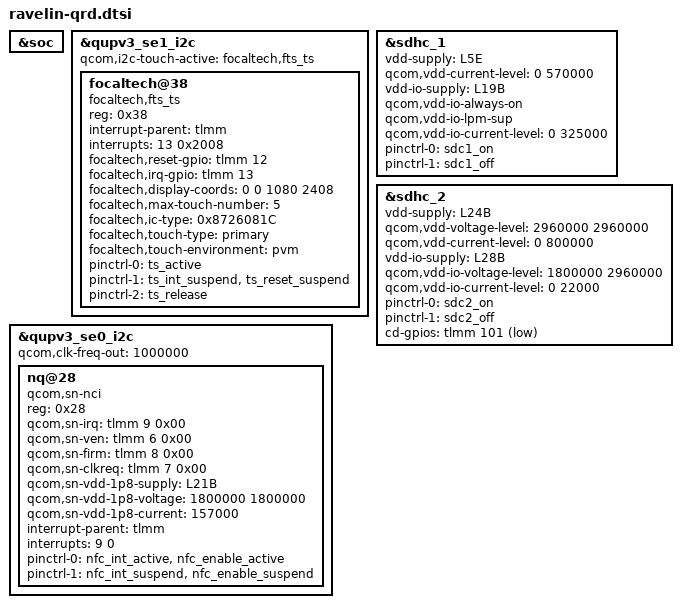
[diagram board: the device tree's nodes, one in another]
#include "ravelin-pmic-overlay.dtsi"
#include "ravelin-pmi632.dtsi"

&soc {
};

&qupv3_se1_i2c {
	#address-cells = <1>;
	#size-cells = <0>;

	status = "ok";
	qcom,i2c-touch-active = "focaltech,fts_ts";

	focaltech@38 {
		compatible = "focaltech,fts_ts";
		status = "ok";
		reg = <0x38>;

		interrupt-parent = <&tlmm>;
		interrupts = <13 0x2008>;
		focaltech,reset-gpio = <&tlmm 12 0x00>;
		focaltech,irq-gpio = <&tlmm 13 0x2008>;
		focaltech,display-coords = <0 0 1080 2408>;
		focaltech,max-touch-number = <5>;
		focaltech,ic-type = <0x8726081C>;
		focaltech,touch-type = "primary";
		focaltech,touch-environment = "pvm";

		pinctrl-names = "pmx_ts_active","pmx_ts_suspend","pmx_ts_release";
		pinctrl-0 = <&ts_active>;
		pinctrl-1 = <&ts_int_suspend &ts_reset_suspend>;
		pinctrl-2 = <&ts_release>;
	};
};

&sdhc_1 {
	status = "ok";
	vdd-supply = <&L5E>;
	qcom,vdd-current-level = <0 570000>;

	vdd-io-supply = <&L19B>;
	qcom,vdd-io-always-on;
	qcom,vdd-io-lpm-sup;
	qcom,vdd-io-current-level = <0 325000>;

	pinctrl-names = "default", "sleep";
	pinctrl-0 = <&sdc1_on>;
	pinctrl-1 = <&sdc1_off>;
};

&sdhc_2 {
	status = "ok";
	vdd-supply = <&L24B>;
	qcom,vdd-voltage-level = <2960000 2960000>;
	qcom,vdd-current-level = <0 800000>;

	vdd-io-supply = <&L28B>;
	qcom,vdd-io-voltage-level = <1800000 2960000>;
	qcom,vdd-io-current-level = <0 22000>;

	pinctrl-names = "default", "sleep";
	pinctrl-0 = <&sdc2_on>;
	pinctrl-1 = <&sdc2_off>;

	cd-gpios = <&tlmm 101 GPIO_ACTIVE_LOW>;
};

&qupv3_se0_i2c {
       status = "ok";
       qcom,clk-freq-out = <1000000>;
       #address-cells = <1>;
       #size-cells = <0>;
       nq@28 {
               compatible = "qcom,sn-nci";
               reg = <0x28>;
               qcom,sn-irq = <&tlmm 9 0x00>;
               qcom,sn-ven = <&tlmm 6 0x00>;
               qcom,sn-firm = <&tlmm 8 0x00>;
               qcom,sn-clkreq = <&tlmm 7 0x00>;
               qcom,sn-vdd-1p8-supply = <&L21B>;
               qcom,sn-vdd-1p8-voltage = <1800000 1800000>;
               qcom,sn-vdd-1p8-current = <157000>;
               interrupt-parent = <&tlmm>;
               interrupts = <9 0>;
               interrupt-names = "nfc_irq";
               pinctrl-names = "nfc_active", "nfc_suspend";
               pinctrl-0 = <&nfc_int_active &nfc_enable_active>;
               pinctrl-1 = <&nfc_int_suspend &nfc_enable_suspend>;
       };
};
